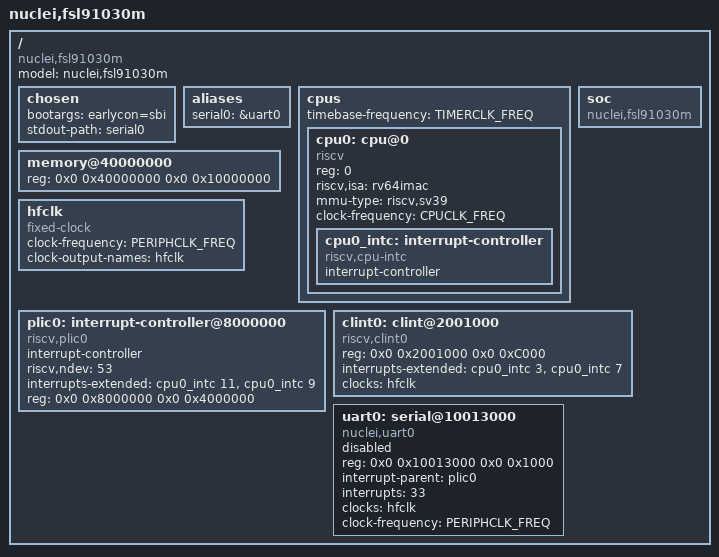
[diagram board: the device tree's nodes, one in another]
/dts-v1/;

#define TIMERCLK_FREQ       100000
#define CPUCLK_FREQ         100000
#define PERIPHCLK_FREQ      100000

/ {
  #address-cells = <2>;
  #size-cells = <2>;
  compatible = "nuclei,fsl91030m";
  model = "nuclei,fsl91030m";

  chosen {
    bootargs = "earlycon=sbi";
    stdout-path = "serial0";
  };

  aliases {
    serial0 = &uart0;
  };

  cpus {
    #address-cells = <1>;
    #size-cells = <0>;
    timebase-frequency = <TIMERCLK_FREQ>;
    cpu0: cpu@0 {
      device_type = "cpu";
      reg = <0>;
      status = "okay";
      compatible = "riscv";
      riscv,isa = "rv64imac";
      mmu-type = "riscv,sv39";
      clock-frequency = <CPUCLK_FREQ>;
      cpu0_intc: interrupt-controller {
        #interrupt-cells = <1>;
        interrupt-controller;
        compatible = "riscv,cpu-intc";
      };
    }; 
  };

  memory@40000000 {
    device_type = "memory";
    reg = <0x0 0x40000000 0x0 0x10000000>;
  };

  soc {
    #address-cells = <2>;
    #size-cells = <2>;
    compatible = "nuclei,fsl91030m", "simple-bus";
    ranges;
  };

  hfclk: hfclk {
    #clock-cells = <0>;
    compatible = "fixed-clock";
    clock-frequency = <PERIPHCLK_FREQ>;
    clock-output-names = "hfclk";
  };

  plic0: interrupt-controller@8000000 {
    #interrupt-cells = <1>;
    compatible = "riscv,plic0";
    interrupt-controller;
    riscv,ndev = <53>;
    interrupts-extended =
          <&cpu0_intc 11 &cpu0_intc 9>;
    reg = <0x0 0x8000000 0x0 0x4000000>;
  };

  clint0: clint@2001000 {
    #interrupt-cells = <1>;
    compatible = "riscv,clint0";
    reg = <0x0 0x2001000 0x0 0xC000>;
    interrupts-extended =
          <&cpu0_intc 3 &cpu0_intc 7>;
    clocks = <&hfclk>;
  };

  uart0: serial@10013000 {
    compatible = "nuclei,uart0";
    reg = <0x0 0x10013000 0x0 0x1000>;
    interrupt-parent = <&plic0>;
    interrupts = <33>;
    clocks = <&hfclk>;
    clock-frequency = <PERIPHCLK_FREQ>;
    status = "disabled";
  };
};
